# LargeDummyDevice register map
File version: 1.0
Registers are 32-bit, read-write, no defined reset value unless marked. A register's access mark holds for its fields unless they carry their own. Offsets are from the block's base; [hi:lo] are bit positions.

## PERIPHERAL_43
Base 0x4002A000
0x04 REG_1 — Register 1
  [32:31] FIELD_18, [30] FIELD_15, [31:29] FIELD_3, [33:29] FIELD_23, [26:24] FIELD_1, [27:24] FIELD_12, [23] FIELD_28, [23:22] FIELD_11, [21] FIELD_2, [25:21] FIELD_26, [25:21] FIELD_27, [21:20] FIELD_8, [20] FIELD_17, [17] FIELD_21, [17] FIELD_24, [19:15] FIELD_19, [13] FIELD_5, [15:13] FIELD_6, [14:13] FIELD_22, [11:8] FIELD_7, [12:8] FIELD_9, [10:8] FIELD_14, [11:7] FIELD_13, [9:5] FIELD_4, [9:5] FIELD_16, [7:5] FIELD_25, [3] FIELD_20, [5:1] FIELD_10
0x08 REG_2 — Register 2
  [22:19] FIELD_4, [20:17] FIELD_1, [10] FIELD_3, [13:9] FIELD_5, [11:8] FIELD_6, [0] FIELD_2
0x0C REG_3 — Register 3
  [34:31] FIELD_6, [29:28] FIELD_18, [25:24] FIELD_17, [22:20] FIELD_16, [22:19] FIELD_15, [19:17] FIELD_1, [17:15] FIELD_11, [16:13] FIELD_20, [14:12] FIELD_10, [15:11] FIELD_14, [10:9] FIELD_2, [12:9] FIELD_4, [11:9] FIELD_5, [13:9] FIELD_13, [11:8] FIELD_12, [9:7] FIELD_19, [6:4] FIELD_3, [5:4] FIELD_7, [6:2] FIELD_8, [5:2] FIELD_9
0x10 REG_4 — Register 4
  [28:26] FIELD_11, [24:23] FIELD_4, [27:23] FIELD_5, [24:21] FIELD_1, [21] FIELD_8, [25:21] FIELD_13, [22:20] FIELD_9, [20] FIELD_22, [17:14] FIELD_2, [16:14] FIELD_7, [16:13] FIELD_16, [12] FIELD_12, [14:11] FIELD_17, [9:6] FIELD_6, [7:3] FIELD_3, [4:2] FIELD_10, [1] FIELD_20, [3:1] FIELD_21, [4:0] FIELD_14, [2:0] FIELD_15, [2:0] FIELD_18, [0] FIELD_19
0x14 REG_5 — Register 5
  [34:31] FIELD_18, [31] FIELD_24, [31:30] FIELD_19, [31:27] FIELD_1, [29:26] FIELD_23, [27:24] FIELD_5, [22] FIELD_7, [23:22] FIELD_14, [24:21] FIELD_2, [23:21] FIELD_8, [23:21] FIELD_12, [21:20] FIELD_4, [16:15] FIELD_13, [19:15] FIELD_22, [12:11] FIELD_3, [13:11] FIELD_17, [14:10] FIELD_20, [14:10] FIELD_26, [9:8] FIELD_15, [9:7] FIELD_16, [8:7] FIELD_25, [6] FIELD_21, [6:4] FIELD_11, [5:2] FIELD_6, [2] FIELD_9, [5:2] FIELD_10
0x18 REG_6 — Register 6
  [32:31] FIELD_6, [33:29] FIELD_3, [30:28] FIELD_5, [8:7] FIELD_4, [4:1] FIELD_1, [1:0] FIELD_2
0x1C REG_7 — Register 7
  [34:31] FIELD_8, [30] FIELD_1, [32:29] FIELD_3, [29] FIELD_7, [29:25] FIELD_5, [19] FIELD_10, [20:17] FIELD_4, [20:16] FIELD_9, [18:15] FIELD_2, [14:12] FIELD_11, [10] FIELD_13, [6:5] FIELD_6, [9:5] FIELD_12, [5:3] FIELD_14
0x20 REG_8 — Register 8
  [30:28] FIELD_1, [30:28] FIELD_9, [29:27] FIELD_14, [29:25] FIELD_13, [29:25] FIELD_16, [24:23] FIELD_21, [20:18] FIELD_20, [18:16] FIELD_15, [13:12] FIELD_3, [14:11] FIELD_8, [12:10] FIELD_2, [14:10] FIELD_4, [9] FIELD_7, [11:8] FIELD_23, [10:7] FIELD_22, [5:4] FIELD_6, [6:4] FIELD_10, [5:4] FIELD_18, [4:3] FIELD_12, [4:1] FIELD_11, [5:1] FIELD_17, [4:1] FIELD_19, [3:0] FIELD_5
0x24 REG_9 — Register 9
  [33:31] FIELD_6, [30:26] FIELD_11, [30:26] FIELD_12, [27:26] FIELD_16, [26:24] FIELD_15, [25:24] FIELD_21, [21] FIELD_4, [23:20] FIELD_1, [19:18] FIELD_19, [17] FIELD_9, [18:16] FIELD_14, [16:14] FIELD_2, [15:13] FIELD_3, [14:11] FIELD_18, [13:10] FIELD_10, [4] FIELD_8, [5:3] FIELD_17, [3] FIELD_20, [6:2] FIELD_13, [4:1] FIELD_5, [2:0] FIELD_7
0x28 REG_10 — Register 10
  [33:31] FIELD_5, [27] FIELD_7, [27:26] FIELD_3, [21:20] FIELD_4, [21:18] FIELD_6, [17:16] FIELD_2, [19:15] FIELD_1
0x2C REG_11 — Register 11
  [33:31] FIELD_10, [34:31] FIELD_11, [29] FIELD_17, [28] FIELD_14, [27:26] FIELD_29, [25] FIELD_19, [25:21] FIELD_22, [22:18] FIELD_24, [19:15] FIELD_20, [19:15] FIELD_21, [18:14] FIELD_9, [17:13] FIELD_6, [15:13] FIELD_15, [16:13] FIELD_23, [12] FIELD_27, [13:10] FIELD_26, [10:9] FIELD_8, [10:7] FIELD_12, [9:6] FIELD_1, [10:6] FIELD_2, [7:5] FIELD_4, [5] FIELD_7, [4] FIELD_5, [8:4] FIELD_16, [4:3] FIELD_28, [4:2] FIELD_18, [5:2] FIELD_25, [1:0] FIELD_3, [4:0] FIELD_13
0x30 REG_12 — Register 12
  [31] FIELD_11, [32:30] FIELD_14, [29] FIELD_8, [30:26] FIELD_6, [27:25] FIELD_19, [24] FIELD_5, [22:18] FIELD_12, [18:17] FIELD_13, [16:12] FIELD_7, [12:11] FIELD_4, [14:10] FIELD_1, [14:10] FIELD_18, [12:9] FIELD_3, [9:7] FIELD_16, [5] FIELD_10, [4] FIELD_15, [7:3] FIELD_17, [3:2] FIELD_9, [4:1] FIELD_2
0x34 REG_13 — Register 13
  [32:30] FIELD_9, [33:30] FIELD_18, [29] FIELD_25, [30:28] FIELD_15, [30:27] FIELD_2, [27] FIELD_5, [31:27] FIELD_19, [25:24] FIELD_20, [25:23] FIELD_23, [23:21] FIELD_26, [20:19] FIELD_11, [21:19] FIELD_14, [21:18] FIELD_1, [18:16] FIELD_7, [19:16] FIELD_10, [17:16] FIELD_12, [14:13] FIELD_17, [15:13] FIELD_22, [11] FIELD_6, [10] FIELD_24, [9] FIELD_27, [11:8] FIELD_13, [11:7] FIELD_8, [8:5] FIELD_21, [8:4] FIELD_16, [4:1] FIELD_4, [2:0] FIELD_3
0x38 REG_14 — Register 14
  [32:31] FIELD_4, [34:30] FIELD_13, [29:28] FIELD_5, [30:27] FIELD_8, [28:24] FIELD_2, [26:24] FIELD_12, [24:20] FIELD_10, [23:19] FIELD_11, [14] FIELD_6, [13:12] FIELD_7, [7:6] FIELD_9, [7:3] FIELD_1, [5:3] FIELD_3
0x3C REG_15 — Register 15
  [34:31] FIELD_9, [33:30] FIELD_7, [28:24] FIELD_4, [22:19] FIELD_1, [20:17] FIELD_6, [19:16] FIELD_14, [13] FIELD_16, [13:12] FIELD_2, [11] FIELD_3, [15:11] FIELD_11, [14:11] FIELD_12, [13:11] FIELD_15, [11:7] FIELD_5, [8:7] FIELD_8, [9:6] FIELD_13, [7:4] FIELD_10
0x40 REG_16 — Register 16
  [12] FIELD_1
0x44 REG_17 — Register 17
  [35:31] FIELD_23, [34:31] FIELD_25, [31] FIELD_32, [33:30] FIELD_4, [32:28] FIELD_9, [30:27] FIELD_8, [28:27] FIELD_14, [26] FIELD_2, [28:25] FIELD_18, [25:23] FIELD_6, [24:23] FIELD_11, [23] FIELD_13, [26:22] FIELD_24, [20] FIELD_17, [21:18] FIELD_1, [19:18] FIELD_12, [18] FIELD_15, [17:15] FIELD_30, [16:13] FIELD_3, [17:13] FIELD_7, [16:12] FIELD_27, [13:12] FIELD_29, [12:11] FIELD_16, [13:11] FIELD_28, [10] FIELD_26, [10:9] FIELD_22, [12:8] FIELD_10, [12:8] FIELD_20, [5:4] FIELD_19, [5:1] FIELD_21, [4:0] FIELD_5, [0] FIELD_31
0x48 REG_18 — Register 18
  [33:31] FIELD_2, [25:24] FIELD_7, [24:23] FIELD_8, [17] FIELD_3, [16] FIELD_5, [15:13] FIELD_4, [10:9] FIELD_6, [11:9] FIELD_9, [9:8] FIELD_11, [6:2] FIELD_1, [2:0] FIELD_10
0x4C REG_19 — Register 19
  [33:31] FIELD_16, [33:30] FIELD_23, [30] FIELD_29, [33:29] FIELD_21, [26] FIELD_12, [24] FIELD_13, [23] FIELD_27, [23:21] FIELD_25, [20] FIELD_5, [23:19] FIELD_4, [22:19] FIELD_22, [17:15] FIELD_2, [17:14] FIELD_1, [16:13] FIELD_6, [17:13] FIELD_28, [15:12] FIELD_18, [13:12] FIELD_20, [12:11] FIELD_19, [10:9] FIELD_26, [8] FIELD_9, [10:6] FIELD_24, [5] FIELD_3, [7:4] FIELD_14, [6:3] FIELD_8, [4:3] FIELD_11, [5:3] FIELD_17, [6:2] FIELD_7, [4:2] FIELD_10, [5:2] FIELD_15
0x50 REG_20 — Register 20
  [26:24] FIELD_7, [24:23] FIELD_6, [17:14] FIELD_1, [15:14] FIELD_4, [11:9] FIELD_3, [5:1] FIELD_5, [2:0] FIELD_2
0x54 REG_21 — Register 21
  [32:31] FIELD_3, [35:31] FIELD_13, [29] FIELD_19, [32:29] FIELD_26, [31:27] FIELD_2, [30:27] FIELD_18, [25] FIELD_1, [25] FIELD_23, [27:24] FIELD_10, [25:22] FIELD_9, [22:20] FIELD_15, [20] FIELD_16, [22:19] FIELD_7, [23:19] FIELD_29, [19:18] FIELD_4, [19:18] FIELD_11, [18:17] FIELD_20, [20:16] FIELD_6, [19:16] FIELD_17, [18:15] FIELD_21, [18:14] FIELD_24, [13:12] FIELD_22, [11:8] FIELD_12, [7:5] FIELD_5, [7:5] FIELD_25, [9:5] FIELD_28, [5:3] FIELD_8, [6:2] FIELD_14, [3:0] FIELD_27
0x58 REG_22 — Register 22
  [29] FIELD_7, [26] FIELD_19, [25] FIELD_11, [28:25] FIELD_21, [27:24] FIELD_4, [24] FIELD_8, [20] FIELD_2, [22:20] FIELD_6, [19:16] FIELD_3, [16] FIELD_9, [17:16] FIELD_13, [17:15] FIELD_12, [15:14] FIELD_10, [13] FIELD_18, [14:12] FIELD_17, [11] FIELD_14, [12:9] FIELD_1, [12:9] FIELD_20, [9:8] FIELD_15, [10:7] FIELD_16, [8:4] FIELD_5
0x5C REG_23 — Register 23
  [32:31] FIELD_14, [31:30] FIELD_4, [30:27] FIELD_10, [28:25] FIELD_8, [26:24] FIELD_2, [24:23] FIELD_5, [23:20] FIELD_3, [17] FIELD_9, [21:17] FIELD_24, [17:14] FIELD_23, [13:12] FIELD_13, [16:12] FIELD_20, [12] FIELD_21, [14:12] FIELD_22, [9] FIELD_15, [13:9] FIELD_17, [11:8] FIELD_11, [9:7] FIELD_18, [10:6] FIELD_1, [7:6] FIELD_16, [7:5] FIELD_25, [5:4] FIELD_19, [6:3] FIELD_6, [6:3] FIELD_7, [4:1] FIELD_12
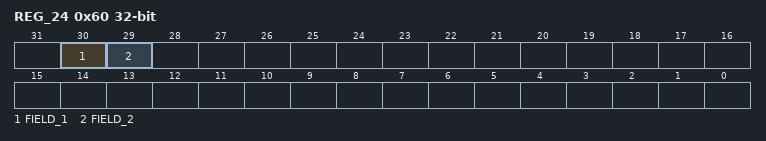
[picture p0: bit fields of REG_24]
0x60 REG_24 — Register 24
  [30] FIELD_1, [29] FIELD_2
0x64 REG_25 — Register 25
  [25] FIELD_8, [28:24] FIELD_4, [24:23] FIELD_1, [21:18] FIELD_3, [18:16] FIELD_6, [13:11] FIELD_2, [13:9] FIELD_7, [9:8] FIELD_9, [7:5] FIELD_5
0x68 REG_26 — Register 26
  [27:25] FIELD_3, [24:22] FIELD_6, [15:12] FIELD_1, [8:6] FIELD_4, [3:1] FIELD_2, [2:1] FIELD_5
0x6C REG_27 — Register 27
  [34:31] FIELD_7, [31:29] FIELD_6, [24:22] FIELD_8, [20:17] FIELD_5, [17:16] FIELD_2, [13:11] FIELD_4, [13:10] FIELD_3, [9:6] FIELD_1
0x70 REG_28 — Register 28
  [25:23] FIELD_2, [26:22] FIELD_5, [25:21] FIELD_4, [22:21] FIELD_8, [22:19] FIELD_1, [23:19] FIELD_6, [7:6] FIELD_7, [7:4] FIELD_3
0x74 REG_29 — Register 29
  [32:30] FIELD_2, [31:29] FIELD_1, [32:28] FIELD_3, [21] FIELD_7, [13:12] FIELD_6, [13:12] FIELD_8, [12:8] FIELD_4, [8] FIELD_9, [6:5] FIELD_5
0x78 REG_30 — Register 30
  [32:31] FIELD_20, [32:30] FIELD_15, [28:26] FIELD_18, [28:26] FIELD_19, [25] FIELD_25, [25:23] FIELD_1, [27:23] FIELD_23, [20:19] FIELD_7, [19:15] FIELD_24, [18:14] FIELD_14, [14] FIELD_17, [16:12] FIELD_27, [12:11] FIELD_11, [14:11] FIELD_13, [11:10] FIELD_9, [9:8] FIELD_16, [6] FIELD_10, [10:6] FIELD_26, [5:4] FIELD_2, [8:4] FIELD_12, [4:3] FIELD_3, [5:3] FIELD_4, [6:2] FIELD_6, [5:2] FIELD_21, [5:2] FIELD_22, [5:1] FIELD_8, [1:0] FIELD_5
0x7C REG_31 — Register 31
  [32:31] FIELD_8, [35:31] FIELD_13, [31] FIELD_18, [33:30] FIELD_14, [29:28] FIELD_11, [29:27] FIELD_1, [28:27] FIELD_19, [28:24] FIELD_16, [22] FIELD_3, [24:21] FIELD_20, [20] FIELD_5, [12] FIELD_4, [13:12] FIELD_7, [16:12] FIELD_17, [8:6] FIELD_2, [6:5] FIELD_6, [7:5] FIELD_9, [4] FIELD_12, [3:1] FIELD_15, [1:0] FIELD_10
0x80 REG_32 — Register 32
  [32:31] FIELD_6, [34:30] FIELD_25, [33:29] FIELD_1, [27:25] FIELD_9, [27:25] FIELD_18, [27:23] FIELD_11, [23:22] FIELD_15, [22:21] FIELD_5, [23:21] FIELD_14, [21:20] FIELD_7, [20] FIELD_26, [24:20] FIELD_31, [21:18] FIELD_23, [21:17] FIELD_13, [16] FIELD_27, [17:16] FIELD_32, [17:15] FIELD_24, [14] FIELD_4, [17:14] FIELD_12, [17:14] FIELD_16, [13] FIELD_17, [14:13] FIELD_29, [14:12] FIELD_3, [13:12] FIELD_20, [10] FIELD_10, [11:8] FIELD_22, [5] FIELD_21, [5] FIELD_28, [3] FIELD_2, [6:2] FIELD_30, [0] FIELD_8, [0] FIELD_19
0x84 REG_33 — Register 33
  [33:29] FIELD_23, [28] FIELD_8, [24] FIELD_11, [26:23] FIELD_3, [26:23] FIELD_14, [22] FIELD_21, [23:21] FIELD_2, [20] FIELD_10, [19] FIELD_5, [22:19] FIELD_12, [20:16] FIELD_1, [16] FIELD_7, [18:16] FIELD_18, [17:15] FIELD_17, [15:13] FIELD_15, [11] FIELD_16, [14:10] FIELD_22, [9] FIELD_6, [8] FIELD_20, [9:7] FIELD_9, [8:7] FIELD_19, [9:6] FIELD_13, [7:5] FIELD_4
